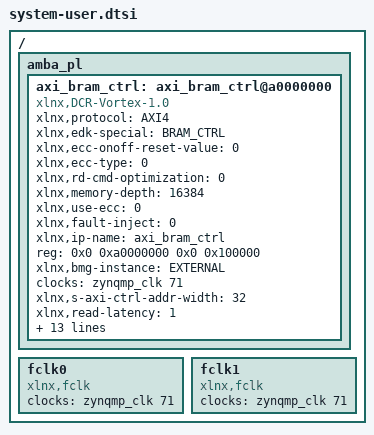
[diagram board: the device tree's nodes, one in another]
/include/ "system-conf.dtsi"
/ {
    amba_pl: amba_pl {
		axi_bram_ctrl: axi_bram_ctrl@a0000000 {
			xlnx,protocol = "AXI4";
			xlnx,edk-special = "BRAM_CTRL";
			compatible = "xlnx,DCR-Vortex-1.0";
			xlnx,ecc-onoff-reset-value = <0>;
			xlnx,ecc-type = <0>;
			xlnx,rd-cmd-optimization = <0>;
			xlnx,memory-depth = <16384>;
			xlnx,use-ecc = <0>;
			xlnx,fault-inject = <0>;
			xlnx,ip-name = "axi_bram_ctrl";
			reg = <0x0 0xa0000000 0x0 0x100000>;
			xlnx,bmg-instance = "EXTERNAL";
			clocks = <&zynqmp_clk 71>;
			xlnx,s-axi-ctrl-addr-width = <32>;
			xlnx,read-latency = <1>;
			xlnx,id-width = <0>;
			xlnx,s-axi-supports-narrow-burst = <0>;
			xlnx,supports-narrow-burst = <0>;
			xlnx,single-port-bram = <0>;
			xlnx,ecc = <0>;
			xlnx,edk-iptype = "PERIPHERAL";
			status = "okay";
			clock-names = "s_axi_aclk";
			xlnx,data-width = <512>;
			xlnx,bram-addr-width = <14>;
			xlnx,bram-inst-mode = "EXTERNAL";
			xlnx,s-axi-ctrl-data-width = <32>;
			xlnx,mem-depth = <16384>;
			xlnx,s-axi-id-width = <1>;
			xlnx,name = "axi_bram_ctrl";
		};
    };
	fclk0: fclk0 {
		status = "okay";
		compatible = "xlnx,fclk";
		clocks = <&zynqmp_clk 71>;
		clock-names = "s00_axi_aclk";
	};
	fclk1: fclk1 {
		status = "okay";
		compatible = "xlnx,fclk";
		clocks = <&zynqmp_clk 71>;
		clock-names = "s_axi_aclk";
	};
};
